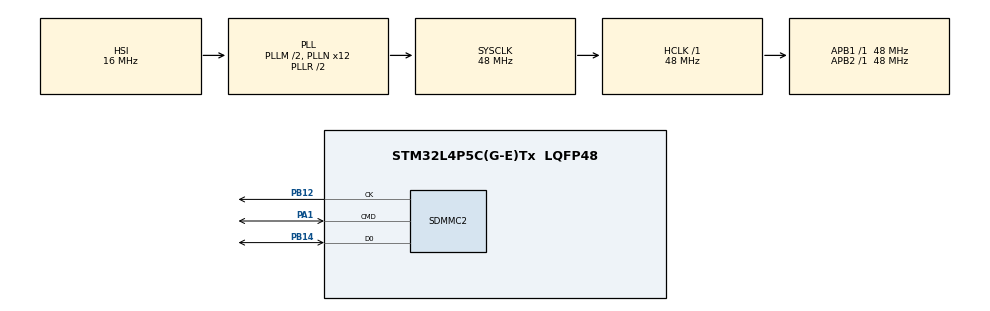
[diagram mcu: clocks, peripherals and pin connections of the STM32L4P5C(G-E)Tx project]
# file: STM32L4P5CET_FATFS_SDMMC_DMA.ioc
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Mcu.Family=STM32L4
RCC.MSI_VALUE=4000000
RCC.PLLSourceVirtual=RCC_PLLSOURCE_HSI
VP_SYS_VS_tim6.Mode=TIM6
RCC.CortexFreq_Value=48000000
FREERTOS.Tasks01=defaultTask,24,512,StartDefaultTask,Default,NULL,Dynamic,NULL,NULL
PA13\ (JTMS/SWDIO).Mode=Trace_Asynchronous_SW
NVIC.TIM6_DAC_IRQn=true\:0\:0\:false\:false\:true\:false\:false\:true
RCC.SYSCLKSource=RCC_SYSCLKSOURCE_PLLCLK
ProjectManager.StackSize=0x400
VP_FREERTOS_VS_CMSIS_V2.Mode=CMSIS_V2
PA14\ (JTCK/SWCLK).Signal=SYS_JTCK-SWCLK
PB3\ (JTDO/TRACESWO).Signal=SYS_JTDO-SWO
ProjectManager.TargetToolchain=STM32CubeIDE
RCC.HCLKFreq_Value=48000000
RCC.APB2TimFreq_Value=48000000
RCC.USBFreq_Value=64000000
RCC.LSE_VALUE=32768
PA1.GPIO_PuPd=GPIO_PULLUP
PA1.Signal=SDMMC2_CMD
RCC.AHBFreq_Value=48000000
VP_FATFS_VS_Generic.Mode=User_defined
PB14.Signal=SDMMC2_D0
RCC.HSE_VALUE=8000000
board=custom
RCC.VCOOutputFreq_Value=96000000
RCC.APB2Freq_Value=48000000
PA1.Mode=SD_1_bit
PB14.Mode=SD_1_bit
RCC.ADCFreq_Value=64000000
PA14\ (JTCK/SWCLK).Mode=Trace_Asynchronous_SW
Mcu.Name=STM32L4P5C(G-E)Tx
SDMMC2.ClockDiv=10
RCC.SYSCLKFreq_VALUE=48000000
Mcu.Package=LQFP48
NVIC.SDMMC2_IRQn=true\:5\:0\:false\:false\:true\:true\:true\:true
PB14.GPIO_PuPd=GPIO_PULLUP
RCC.PLLM1=2
PB12.Mode=SD_1_bit
NVIC.TimeBase=TIM6_DAC_IRQn
NVIC.TimeBaseIP=TIM6
ProjectManager.HeapSize=0x200
RCC.HSI_VALUE=16000000
NVIC.PriorityGroup=NVIC_PRIORITYGROUP_4
PB3\ (JTDO/TRACESWO).Mode=Trace_Asynchronous_SW
RCC.PLLN=12
RCC.APB1TimFreq_Value=48000000
RCC.APB1Freq_Value=48000000
PB12.Signal=SDMMC2_CK
RCC.HSI48_VALUE=48000000
PA13\ (JTMS/SWDIO).Signal=SYS_JTMS-SWDIO

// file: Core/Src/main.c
/* USER CODE BEGIN Header */
/**
 ******************************************************************************
 * @file           : main.c
 * @brief          : Main program body
 ******************************************************************************
 * @attention
 *
 * <h2><center>&copy; Copyright (c) 2021 STMicroelectronics.
 * All rights reserved.</center></h2>
 *
 * This software component is licensed by ST under BSD 3-Clause license,
 * the "License"; You may not use this file except in compliance with the
 * License. You may obtain a copy of the License at:
 *                        opensource.org/licenses/BSD-3-Clause
 *
 ******************************************************************************
 */
/* USER CODE END Header */
#include "main.h"
#include "cmsis_os.h"
#include "fatfs.h"

/* USER CODE BEGIN Includes */
#include <stdio.h>
/* USER CODE END Includes */

SD_HandleTypeDef hsd2;

/* Definitions for defaultTask */
osThreadId_t defaultTaskHandle;
const osThreadAttr_t defaultTask_attributes = {
  .name = "defaultTask",
  .stack_size = 512 * 4,
  .priority = (osPriority_t) osPriorityNormal,
};
/* USER CODE BEGIN PV */
extern char USERPath[4];
extern FATFS USERFatFS;
extern FIL USERFile;
/* USER CODE END PV */

void SystemClock_Config(void);
static void MX_GPIO_Init(void);
static void MX_SDMMC2_SD_Init(void);
void StartDefaultTask(void *argument);

int main(void)
{

  /* MCU Configuration--------------------------------------------------------*/

  /* Reset of all peripherals, Initializes the Flash interface and the Systick. */
  HAL_Init();

  /* Configure the system clock */
  SystemClock_Config();

  /* Initialize all configured peripherals */
  MX_GPIO_Init();
  MX_SDMMC2_SD_Init();
  MX_FATFS_Init();

  /* Init scheduler */
  osKernelInitialize();

  /* Create the thread(s) */
  /* creation of defaultTask */
  defaultTaskHandle = osThreadNew(StartDefaultTask, NULL, &defaultTask_attributes);

  /* Start scheduler */
  osKernelStart();

  /* We should never get here as control is now taken by the scheduler */
  /* Infinite loop */
	while (1) {

	}
}

void SystemClock_Config(void)
{
  RCC_OscInitTypeDef RCC_OscInitStruct = {0};
  RCC_ClkInitTypeDef RCC_ClkInitStruct = {0};
  RCC_PeriphCLKInitTypeDef PeriphClkInit = {0};

  /** Configure the main internal regulator output voltage
  */
  if (HAL_PWREx_ControlVoltageScaling(PWR_REGULATOR_VOLTAGE_SCALE1) != HAL_OK)
  {
    Error_Handler();
  }
  /** Initializes the RCC Oscillators according to the specified parameters
  * in the RCC_OscInitTypeDef structure.
  */
  RCC_OscInitStruct.OscillatorType = RCC_OSCILLATORTYPE_HSI;
  RCC_OscInitStruct.HSIState = RCC_HSI_ON;
  RCC_OscInitStruct.HSICalibrationValue = RCC_HSICALIBRATION_DEFAULT;
  RCC_OscInitStruct.PLL.PLLState = RCC_PLL_ON;
  RCC_OscInitStruct.PLL.PLLSource = RCC_PLLSOURCE_HSI;
  RCC_OscInitStruct.PLL.PLLM = 2;
  RCC_OscInitStruct.PLL.PLLN = 12;
  RCC_OscInitStruct.PLL.PLLP = RCC_PLLP_DIV2;
  RCC_OscInitStruct.PLL.PLLQ = RCC_PLLQ_DIV2;
  RCC_OscInitStruct.PLL.PLLR = RCC_PLLR_DIV2;
  if (HAL_RCC_OscConfig(&RCC_OscInitStruct) != HAL_OK)
  {
    Error_Handler();
  }
  /** Initializes the CPU, AHB and APB buses clocks
  */
  RCC_ClkInitStruct.ClockType = RCC_CLOCKTYPE_HCLK|RCC_CLOCKTYPE_SYSCLK
                              |RCC_CLOCKTYPE_PCLK1|RCC_CLOCKTYPE_PCLK2;
  RCC_ClkInitStruct.SYSCLKSource = RCC_SYSCLKSOURCE_PLLCLK;
  RCC_ClkInitStruct.AHBCLKDivider = RCC_SYSCLK_DIV1;
  RCC_ClkInitStruct.APB1CLKDivider = RCC_HCLK_DIV1;
  RCC_ClkInitStruct.APB2CLKDivider = RCC_HCLK_DIV1;

  if (HAL_RCC_ClockConfig(&RCC_ClkInitStruct, FLASH_LATENCY_2) != HAL_OK)
  {
    Error_Handler();
  }
  PeriphClkInit.PeriphClockSelection = RCC_PERIPHCLK_SDMMC1;
  PeriphClkInit.Sdmmc1ClockSelection = RCC_SDMMC1CLKSOURCE_PLLP;
  if (HAL_RCCEx_PeriphCLKConfig(&PeriphClkInit) != HAL_OK)
  {
    Error_Handler();
  }
}

static void MX_SDMMC2_SD_Init(void)
{

  hsd2.Instance = SDMMC2;
  hsd2.Init.ClockEdge = SDMMC_CLOCK_EDGE_RISING;
  hsd2.Init.ClockPowerSave = SDMMC_CLOCK_POWER_SAVE_DISABLE;
  hsd2.Init.BusWide = SDMMC_BUS_WIDE_1B;
  hsd2.Init.HardwareFlowControl = SDMMC_HARDWARE_FLOW_CONTROL_DISABLE;
  hsd2.Init.ClockDiv = 10;
  hsd2.Init.Transceiver = SDMMC_TRANSCEIVER_DISABLE;
  if (HAL_SD_Init(&hsd2) != HAL_OK)
  {
    Error_Handler();
  }

}

static void MX_GPIO_Init(void)
{

  /* GPIO Ports Clock Enable */
  __HAL_RCC_GPIOA_CLK_ENABLE();
  __HAL_RCC_GPIOB_CLK_ENABLE();

}

/* USER CODE BEGIN 4 */
//In order to use printf to debug through SWO
int _write(int32_t file, uint8_t *ptr, int32_t len)
{
	for (int i = 0; i < len; i++) {
		ITM_SendChar(*ptr++);
	}
	return len;
}

/*
 * Simple test function to create file "STM32.TXT"
 * write text "hello from stm32!!!"
 * and close file.
 */
void test(void)
{
	if (f_mount(&USERFatFS, (TCHAR const*) USERPath, 0) != FR_OK) {
		printf("app_sd_test: f_mount error\n");
		return;
	}

	if (f_open(&USERFile, "STM32.TXT", FA_CREATE_ALWAYS | FA_WRITE) != FR_OK) {
		printf("app_sd_test: f_open error\n");
		return;
	}

	uint8_t text[] = "hello from stm32!!!";
	uint32_t bw;
	FRESULT res = f_write(&USERFile, text, sizeof(text), &bw);
	if (res != FR_OK || bw == 0) {
		printf("app_sd_test: f_write error\n");
		return;
	}
	f_close(&USERFile);

	printf("app_sd_test: File STM32.TXT created\n");
}
/* USER CODE END 4 */

void StartDefaultTask(void *argument)
{
  /* USER CODE BEGIN 5 */
	test();
	/* Infinite loop */
	for (;;) {
		osDelay(1);
	}
  /* USER CODE END 5 */
}

 /**
  * @brief  Period elapsed callback in non blocking mode
  * @note   This function is called  when TIM6 interrupt took place, inside
  * HAL_TIM_IRQHandler(). It makes a direct call to HAL_IncTick() to increment
  * a global variable "uwTick" used as application time base.
  * @param  htim : TIM handle
  * @retval None
  */
void HAL_TIM_PeriodElapsedCallback(TIM_HandleTypeDef *htim)
{
  if (htim->Instance == TIM6) {
    HAL_IncTick();
  }
}

void Error_Handler(void)
{
	__disable_irq();
	while (1) {
	}
}

/************************ (C) COPYRIGHT STMicroelectronics *****END OF FILE****/
